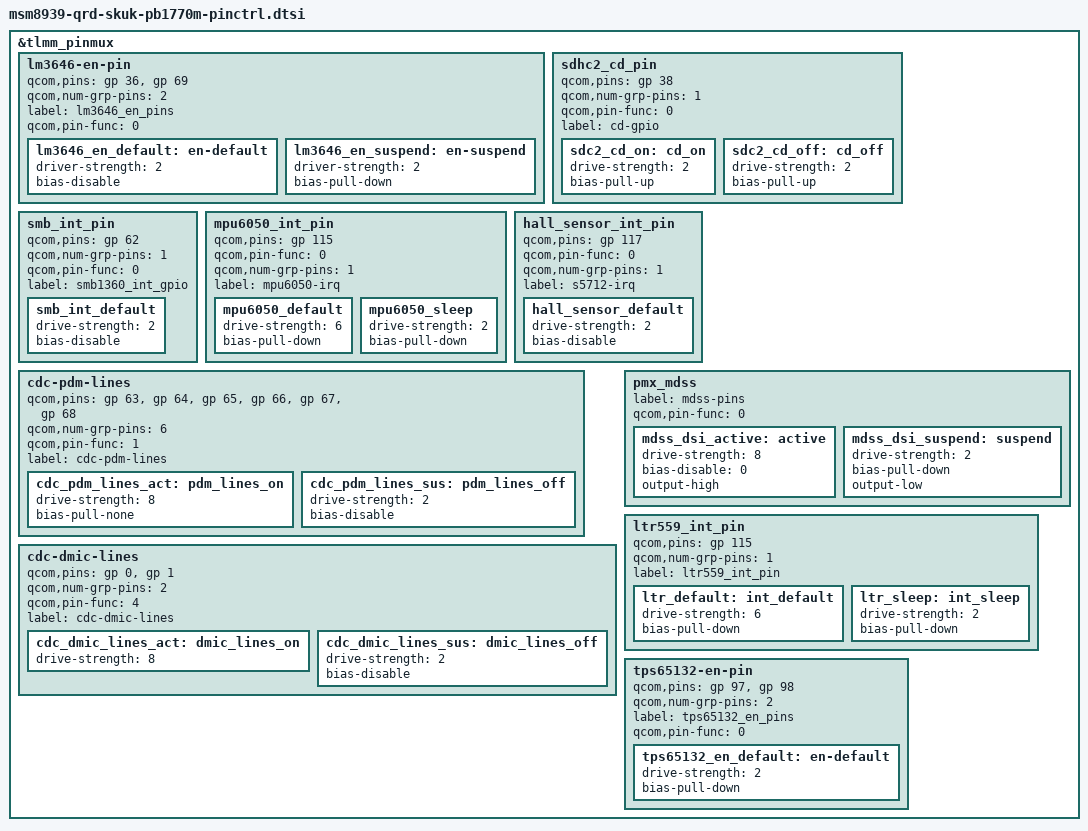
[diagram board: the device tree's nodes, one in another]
/* Copyright (c) 2020, The Linux Foundation. All rights reserved.
 * Copyright (c) 2020, the_shahnawaz_sheikh
 *
 * This program is free software; you can redistribute it and/or modify
 * it under the terms of the GNU General Public License version 2 and
 * only version 2 as published by the Free Software Foundation.
 *
 * This program is distributed in the hope that it will be useful,
 * but WITHOUT ANY WARRANTY; without even the implied warranty of
 * MERCHANTABILITY or FITNESS FOR A PARTICULAR PURPOSE.  See the
 * GNU General Public License for more details.
 */

&tlmm_pinmux {
      
	  
	  
	  /delete-node/ SGM3780_pins;
	  
	  
	  lm3646-en-pin {
		qcom,pins = <&gp 36>, <&gp 69>;
		qcom,num-grp-pins = <2>;
		label = "lm3646_en_pins";
		qcom,pin-func = <0>;

		lm3646_en_default: en-default {
			driver-strength = <2>;
			bias-disable;
		};
		lm3646_en_suspend: en-suspend {
			driver-strength = <2>;
			bias-pull-down;
		};
	};


     
	 sdhc2_cd_pin {
			qcom,pins = <&gp 38>;
			qcom,num-grp-pins = <1>;
			qcom,pin-func = <0>;
			label = "cd-gpio";
			sdc2_cd_on: cd_on {
				drive-strength = <2>;
				bias-pull-up;
			};
			sdc2_cd_off: cd_off {
				drive-strength = <2>;
				/delete-property/ bias-disable;
				bias-pull-up;
			};
		};
		
	
	smb_int_pin {
			qcom,pins = <&gp 62>;
			qcom,num-grp-pins = <1>;
			qcom,pin-func = <0>;
			label = "smb1360_int_gpio";
			smb_int_default: smb_int_default {
				drive-strength = <2>;	/* 2 MA */
				/delete-property/ bias-pull-up;
				bias-disable;		/* NO PULL*/
			};
		};
			  
			  
	mpu6050_int_pin {
			/* Gyroscope and accelerometer sensor combo */
			qcom,pins = <&gp 115>;
			qcom,pin-func = <0>;
			qcom,num-grp-pins = <1>;
			label = "mpu6050-irq";
			mpu6050_default: mpu6050_default {
				drive-strength = <6>;
				bias-pull-down;
			};
			mpu6050_sleep: mpu6050_sleep {
				drive-strength = <2>;
			/delete-property/	bias-pull-up;
				bias-pull-down;
			};
		};
	 
	 
		hall_sensor_int_pin {
			qcom,pins = <&gp 117>;
			qcom,pin-func = <0>;
			qcom,num-grp-pins = <1>;
			label = "s5712-irq";
			hall_sensor_default: hall_sensor_default {
				drive-strength = <2>;
				//bias-pull-up;
				bias-disable; 
			};
		};
		 
		
		
		
		
		cdc-pdm-lines {
			qcom,pins = <&gp 63>, <&gp 64>, <&gp 65>,
					<&gp 66>, <&gp 67>, <&gp 68>;
			qcom,num-grp-pins = <6>;
			qcom,pin-func = <1>;
			label = "cdc-pdm-lines";
			cdc_pdm_lines_act: pdm_lines_on {
				drive-strength = <8>;
				bias-pull-none;
			};
			cdc_pdm_lines_sus: pdm_lines_off {
				drive-strength = <2>;
			/delete-property/	bias-pull-down;
				bias-disable;
			};
		};

		cdc-dmic-lines {
			qcom,pins = <&gp 0>, <&gp 1>;
			qcom,num-grp-pins = <2>;
			qcom,pin-func = <4>;
			label = "cdc-dmic-lines";
			cdc_dmic_lines_act: dmic_lines_on {
				drive-strength = <8>;
			};
			cdc_dmic_lines_sus: dmic_lines_off {
				drive-strength = <2>;
				bias-disable;
			};
		};
		
		
		pmx_mdss: pmx_mdss {
			label = "mdss-pins";
			qcom,pin-func = <0>;

			mdss_dsi_active: active {
				drive-strength = <8>; /* 8 mA */
				bias-disable = <0>; /* no pull */
				output-high;
			};
			mdss_dsi_suspend: suspend {
				drive-strength = <2>; /* 2 mA */
				bias-pull-down; /* pull down */
				output-low;
			};
		};
	 
	 

     ltr559_int_pin {
		qcom,pins = <&gp 115>;
		qcom,num-grp-pins = <1>;
		label = "ltr559_int_pin";
		ltr_default: int_default {
			  drive-strength = <6>;
			  bias-pull-down;
		};
		ltr_sleep: int_sleep {
			  drive-strength = <2>;
			  bias-pull-down;
		};
	};

	tps65132-en-pin {
		qcom,pins = <&gp 97>, <&gp 98>;
		qcom,num-grp-pins = <2>;
		label = "tps65132_en_pins";
		qcom,pin-func = <0>;

		tps65132_en_default: en-default {
			drive-strength = <2>;
			bias-pull-down;
		};
	};
};
     


